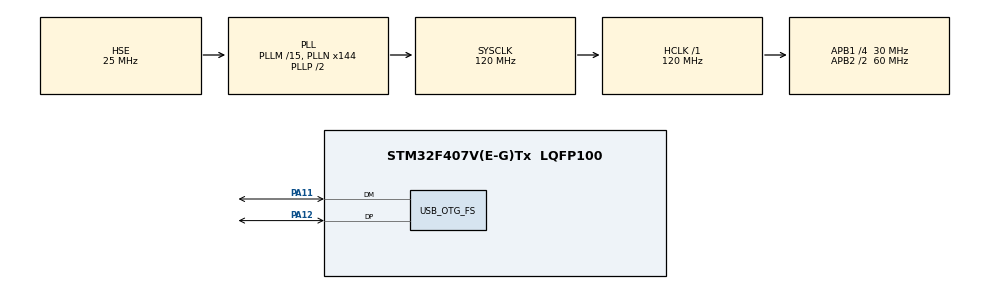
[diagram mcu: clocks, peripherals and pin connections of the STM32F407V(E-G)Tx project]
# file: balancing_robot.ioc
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FREERTOS.Tasks01=defaultTask,0,128,StartDefaultTask,Default,NULL
Mcu.Family=STM32F4
Mcu.Name=STM32F407V(E-G)Tx
Mcu.Package=LQFP100
NVIC.OTG_FS_IRQn=true\:5\:0\:false\:false\:true\:true\:true\:true
NVIC.PriorityGroup=NVIC_PRIORITYGROUP_4
PA11.Mode=Device_Only
PA11.Signal=USB_OTG_FS_DM
PA12.Mode=Device_Only
PA12.Signal=USB_OTG_FS_DP
PA13.Mode=JTAG_5_pins
PA13.Signal=SYS_JTMS-SWDIO
PA14.Mode=JTAG_5_pins
PA14.Signal=SYS_JTCK-SWCLK
PA15.Mode=JTAG_5_pins
PA15.Signal=SYS_JTDI
PB3.Mode=JTAG_5_pins
PB3.Signal=SYS_JTDO-SWO
PB4.Mode=JTAG_5_pins
PB4.Signal=SYS_JTRST
PH0-OSC_IN.Mode=HSE-External-Oscillator
PH0-OSC_IN.Signal=RCC_OSC_IN
PH1-OSC_OUT.Mode=HSE-External-Oscillator
PH1-OSC_OUT.Signal=RCC_OSC_OUT
ProjectManager.HeapSize=0x200
ProjectManager.StackSize=0x400
ProjectManager.TargetToolchain=SW4STM32
RCC.48MHZClocksFreq_Value=48000000
RCC.AHBFreq_Value=120000000
RCC.APB1CLKDivider=RCC_HCLK_DIV4
RCC.APB1Freq_Value=30000000
RCC.APB1TimFreq_Value=60000000
RCC.APB2CLKDivider=RCC_HCLK_DIV2
RCC.APB2Freq_Value=60000000
RCC.APB2TimFreq_Value=120000000
RCC.CortexFreq_Value=120000000
RCC.HCLKFreq_Value=120000000
RCC.HSE_VALUE=25000000
RCC.HSI_VALUE=16000000
RCC.LSE_VALUE=32768
RCC.PLLM=15
RCC.PLLN=144
RCC.PLLQ=5
RCC.SYSCLKFreq_VALUE=120000000
RCC.SYSCLKSource=RCC_SYSCLKSOURCE_PLLCLK
RCC.VCOOutputFreq_Value=240000000
USB_DEVICE.CLASS_NAME_FS=CDC
USB_DEVICE.VirtualMode-CDC_FS=Cdc
USB_DEVICE.VirtualModeFS=Cdc_FS
USB_OTG_FS.VirtualMode=Device_Only
VP_FREERTOS_VS_CMSIS_V1.Mode=CMSIS_V1
VP_USB_DEVICE_VS_USB_DEVICE_CDC_FS.Mode=CDC_FS
board=custom

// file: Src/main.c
/* USER CODE BEGIN Header */
/**
  ******************************************************************************
  * @file           : main.c
  * @brief          : Main program body
  ******************************************************************************
  * @attention
  *
  * <h2><center>&copy; Copyright (c) 2019 STMicroelectronics.
  * All rights reserved.</center></h2>
  *
  * This software component is licensed by ST under Ultimate Liberty license
  * SLA0044, the "License"; You may not use this file except in compliance with
  * the License. You may obtain a copy of the License at:
  *                             www.st.com/SLA0044
  *
  ******************************************************************************
  */
/* USER CODE END Header */

#include "main.h"
#include "cmsis_os.h"
#include "usb_device.h"

/* USER CODE BEGIN Includes */
#include "general.h"
/* USER CODE END Includes */

osThreadId defaultTaskHandle;

void SystemClock_Config(void);
static void MX_GPIO_Init(void);
void StartDefaultTask(void const * argument);

int main(void)
{
  /* USER CODE BEGIN 1 */
    global_initialize_cpp();
  /* USER CODE END 1 */

  /* MCU Configuration--------------------------------------------------------*/

  /* Reset of all peripherals, Initializes the Flash interface and the Systick. */
  HAL_Init();

  /* Configure the system clock */
  SystemClock_Config();

  /* Initialize all configured peripherals */
  MX_GPIO_Init();

  /* Create the thread(s) */
  /* definition and creation of defaultTask */
  osThreadDef(defaultTask, StartDefaultTask, osPriorityNormal, 0, 128);
  defaultTaskHandle = osThreadCreate(osThread(defaultTask), NULL);

  /* Start scheduler */
  osKernelStart();

  /* We should never get here as control is now taken by the scheduler */

  /* Infinite loop */
  while (1)
  {

  }
}

void SystemClock_Config(void)
{
  RCC_OscInitTypeDef RCC_OscInitStruct = {0};
  RCC_ClkInitTypeDef RCC_ClkInitStruct = {0};

  /** Configure the main internal regulator output voltage
  */
  __HAL_RCC_PWR_CLK_ENABLE();
  __HAL_PWR_VOLTAGESCALING_CONFIG(PWR_REGULATOR_VOLTAGE_SCALE1);
  /** Initializes the CPU, AHB and APB busses clocks
  */
  RCC_OscInitStruct.OscillatorType = RCC_OSCILLATORTYPE_HSE;
  RCC_OscInitStruct.HSEState = RCC_HSE_ON;
  RCC_OscInitStruct.PLL.PLLState = RCC_PLL_ON;
  RCC_OscInitStruct.PLL.PLLSource = RCC_PLLSOURCE_HSE;
  RCC_OscInitStruct.PLL.PLLM = 15;
  RCC_OscInitStruct.PLL.PLLN = 144;
  RCC_OscInitStruct.PLL.PLLP = RCC_PLLP_DIV2;
  RCC_OscInitStruct.PLL.PLLQ = 5;
  if (HAL_RCC_OscConfig(&RCC_OscInitStruct) != HAL_OK)
  {
    Error_Handler();
  }
  /** Initializes the CPU, AHB and APB busses clocks
  */
  RCC_ClkInitStruct.ClockType = RCC_CLOCKTYPE_HCLK|RCC_CLOCKTYPE_SYSCLK
                              |RCC_CLOCKTYPE_PCLK1|RCC_CLOCKTYPE_PCLK2;
  RCC_ClkInitStruct.SYSCLKSource = RCC_SYSCLKSOURCE_PLLCLK;
  RCC_ClkInitStruct.AHBCLKDivider = RCC_SYSCLK_DIV1;
  RCC_ClkInitStruct.APB1CLKDivider = RCC_HCLK_DIV4;
  RCC_ClkInitStruct.APB2CLKDivider = RCC_HCLK_DIV2;

  if (HAL_RCC_ClockConfig(&RCC_ClkInitStruct, FLASH_LATENCY_3) != HAL_OK)
  {
    Error_Handler();
  }
}

static void MX_GPIO_Init(void)
{
  GPIO_InitTypeDef GPIO_InitStruct = {0};

  /* GPIO Ports Clock Enable */
  __HAL_RCC_GPIOH_CLK_ENABLE();
  __HAL_RCC_GPIOA_CLK_ENABLE();
  __HAL_RCC_GPIOB_CLK_ENABLE();

  /*Configure GPIO pin Output Level */
  HAL_GPIO_WritePin(GPIOB, GPIO_PIN_9, GPIO_PIN_RESET);

  /*Configure GPIO pin : PB9 */
  GPIO_InitStruct.Pin = GPIO_PIN_9;
  GPIO_InitStruct.Mode = GPIO_MODE_OUTPUT_PP;
  GPIO_InitStruct.Pull = GPIO_NOPULL;
  GPIO_InitStruct.Speed = GPIO_SPEED_FREQ_LOW;
  HAL_GPIO_Init(GPIOB, &GPIO_InitStruct);

}

void StartDefaultTask(void const * argument)
{
  /* init code for USB_DEVICE */
  MX_USB_DEVICE_Init();

  for(;;)
  {
    osDelay(1);
  }
}

void Error_Handler(void)
{
}

/************************ (C) COPYRIGHT STMicroelectronics *****END OF FILE****/
